VERSION "SIMULATED_UVFR_0.1"

NS_ :

BS_:

BU_: SIM_ECU SIM_GPS SIM_HARNESS TELEMETRY_NODE

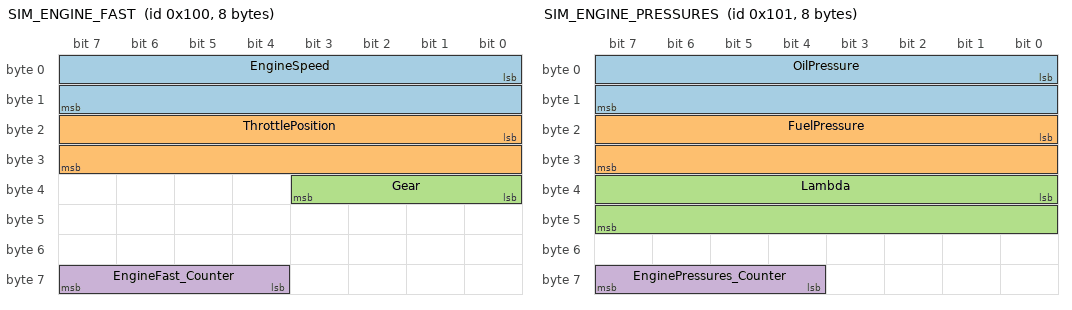
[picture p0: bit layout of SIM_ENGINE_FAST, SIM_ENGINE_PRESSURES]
BO_ 256 SIM_ENGINE_FAST: 8 SIM_ECU
 SG_ EngineSpeed : 0|16@1+ (1,0) [0|16000] "rpm" TELEMETRY_NODE
 SG_ ThrottlePosition : 16|16@1+ (0.1,0) [0|100] "%" TELEMETRY_NODE
 SG_ Gear : 32|4@1+ (1,0) [0|6] "" TELEMETRY_NODE
 SG_ EngineFast_Counter : 60|4@1+ (1,0) [0|15] "" TELEMETRY_NODE

BO_ 257 SIM_ENGINE_PRESSURES: 8 SIM_ECU
 SG_ OilPressure : 0|16@1+ (0.1,0) [0|1000] "kPa" TELEMETRY_NODE
 SG_ FuelPressure : 16|16@1+ (0.1,0) [0|1000] "kPa" TELEMETRY_NODE
 SG_ Lambda : 32|16@1+ (0.001,0) [0|5] "lambda" TELEMETRY_NODE
 SG_ EnginePressures_Counter : 60|4@1+ (1,0) [0|15] "" TELEMETRY_NODE

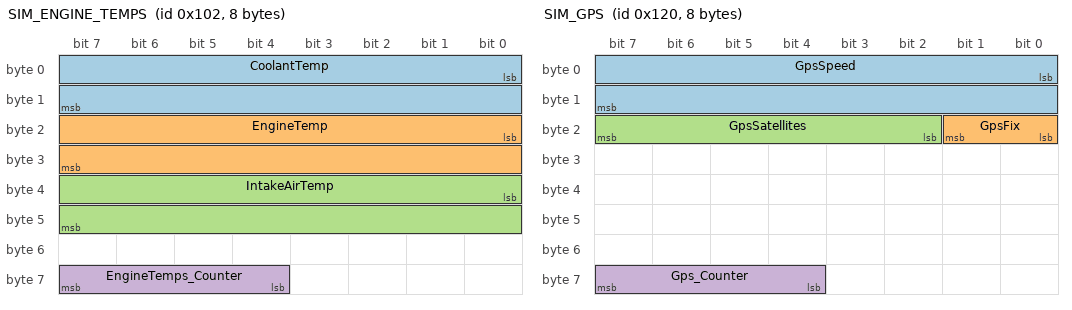
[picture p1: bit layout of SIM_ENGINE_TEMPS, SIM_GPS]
BO_ 258 SIM_ENGINE_TEMPS: 8 SIM_ECU
 SG_ CoolantTemp : 0|16@1+ (0.1,-40) [-40|150] "degC" TELEMETRY_NODE
 SG_ EngineTemp : 16|16@1+ (0.1,-40) [-40|200] "degC" TELEMETRY_NODE
 SG_ IntakeAirTemp : 32|16@1+ (0.1,-40) [-40|120] "degC" TELEMETRY_NODE
 SG_ EngineTemps_Counter : 60|4@1+ (1,0) [0|15] "" TELEMETRY_NODE

BO_ 259 SIM_ELECTRICAL: 8 SIM_ECU
 SG_ BatteryVoltage : 0|16@1+ (0.01,0) [0|20] "V" TELEMETRY_NODE
 SG_ Electrical_Counter : 60|4@1+ (1,0) [0|15] "" TELEMETRY_NODE

BO_ 272 SIM_VEHICLE: 8 SIM_ECU
 SG_ VehicleSpeed : 0|16@1+ (0.01,0) [0|200] "km/h" TELEMETRY_NODE
 SG_ Vehicle_Counter : 60|4@1+ (1,0) [0|15] "" TELEMETRY_NODE

BO_ 288 SIM_GPS: 8 SIM_GPS
 SG_ GpsSpeed : 0|16@1+ (0.01,0) [0|200] "km/h" TELEMETRY_NODE
 SG_ GpsFix : 16|2@1+ (1,0) [0|3] "" TELEMETRY_NODE
 SG_ GpsSatellites : 18|6@1+ (1,0) [0|63] "" TELEMETRY_NODE
 SG_ Gps_Counter : 60|4@1+ (1,0) [0|15] "" TELEMETRY_NODE

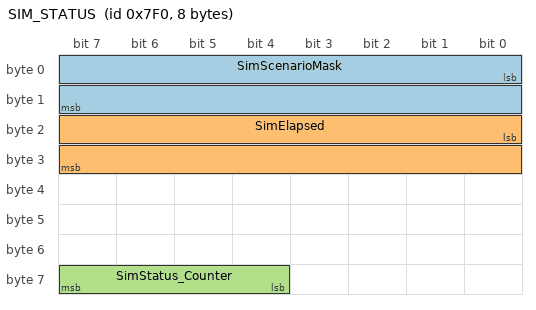
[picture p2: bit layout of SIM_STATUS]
BO_ 2032 SIM_STATUS: 8 SIM_HARNESS
 SG_ SimScenarioMask : 0|16@1+ (1,0) [0|65535] "" TELEMETRY_NODE
 SG_ SimElapsed : 16|16@1+ (1,0) [0|65535] "s" TELEMETRY_NODE
 SG_ SimStatus_Counter : 60|4@1+ (1,0) [0|15] "" TELEMETRY_NODE

CM_ "SIMULATED CAN DATABASE for the UVFR telemetry Phase 0 lab. Every message ID, signal, scaling and range in this file is SIMULATED and invented for testing. None of it is the real UVFR vehicle CAN database. Replace this file with the real DBC before using real vehicle data. Convention: a raw value with all bits set (0xFFFF for 16-bit signals) means sensor fault / not available and decodes outside the signal range.";
CM_ BU_ SIM_ECU "SIMULATED engine ECU (fake_ecu.py). Not a real UVFR node.";
CM_ BU_ SIM_GPS "SIMULATED GPS receiver (fake_ecu.py). Not a real UVFR node.";
CM_ BU_ SIM_HARNESS "Simulation harness metadata. Exists only in the Phase 0 lab, never on the car.";
CM_ BU_ TELEMETRY_NODE "Passive telemetry listener (car node). Receives only, never transmits on the vehicle bus.";
CM_ BO_ 256 "SIMULATED ID 0x100. Fast engine data at 100 Hz.";
CM_ SG_ 256 EngineSpeed "SIMULATED. Crankshaft speed.";
CM_ SG_ 256 ThrottlePosition "SIMULATED. Throttle opening.";
CM_ SG_ 256 Gear "SIMULATED. Engaged gear, 0 = neutral.";
CM_ SG_ 256 EngineFast_Counter "SIMULATED. Rolling counter, increments every transmission.";
CM_ BO_ 257 "SIMULATED ID 0x101. Engine pressures and mixture at 50 Hz.";
CM_ SG_ 257 OilPressure "SIMULATED. Engine oil gallery pressure (gauge).";
CM_ SG_ 257 FuelPressure "SIMULATED. Fuel rail pressure (gauge).";
CM_ SG_ 257 Lambda "SIMULATED. Wideband lambda, 1.0 = stoichiometric.";
CM_ SG_ 257 EnginePressures_Counter "SIMULATED. Rolling counter, increments every transmission.";
CM_ BO_ 258 "SIMULATED ID 0x102. Engine temperatures at 10 Hz.";
CM_ SG_ 258 CoolantTemp "SIMULATED. Coolant temperature at engine outlet.";
CM_ SG_ 258 EngineTemp "SIMULATED. Cylinder head temperature.";
CM_ SG_ 258 IntakeAirTemp "SIMULATED. Intake air temperature after the restrictor.";
CM_ SG_ 258 EngineTemps_Counter "SIMULATED. Rolling counter, increments every transmission.";
CM_ BO_ 259 "SIMULATED ID 0x103. Electrical system at 10 Hz.";
CM_ SG_ 259 BatteryVoltage "SIMULATED. Low-voltage system voltage at the ECU.";
CM_ SG_ 259 Electrical_Counter "SIMULATED. Rolling counter, increments every transmission.";
CM_ BO_ 272 "SIMULATED ID 0x110. Vehicle speed at 50 Hz.";
CM_ SG_ 272 VehicleSpeed "SIMULATED. Vehicle speed from front (undriven) wheel speed sensors.";
CM_ SG_ 272 Vehicle_Counter "SIMULATED. Rolling counter, increments every transmission.";
CM_ BO_ 288 "SIMULATED ID 0x120. GPS at 10 Hz.";
CM_ SG_ 288 GpsSpeed "SIMULATED. Ground speed from GPS.";
CM_ SG_ 288 GpsFix "SIMULATED. GPS fix type.";
CM_ SG_ 288 GpsSatellites "SIMULATED. Satellites used in the fix.";
CM_ SG_ 288 Gps_Counter "SIMULATED. Rolling counter, increments every transmission.";
CM_ BO_ 2032 "SIMULATION HARNESS ID 0x7F0 at 1 Hz. Reports which fault scenarios the fake ECU is running. Lab only; does not exist on any car.";
CM_ SG_ 2032 SimScenarioMask "Bitmask of active simulated fault scenarios, 0 = normal. Bit meanings are defined in simulator/scenarios.";
CM_ SG_ 2032 SimElapsed "Seconds since the fake ECU started (wraps at 65535).";
CM_ SG_ 2032 SimStatus_Counter "Rolling counter, increments every transmission.";
BA_DEF_ BO_ "GenMsgCycleTime" INT 0 65535;
BA_DEF_ "BusType" STRING ;
BA_DEF_DEF_ "GenMsgCycleTime" 0;
BA_DEF_DEF_ "BusType" "CAN";
BA_ "GenMsgCycleTime" BO_ 256 10;
BA_ "GenMsgCycleTime" BO_ 257 20;
BA_ "GenMsgCycleTime" BO_ 258 100;
BA_ "GenMsgCycleTime" BO_ 259 100;
BA_ "GenMsgCycleTime" BO_ 272 20;
BA_ "GenMsgCycleTime" BO_ 288 100;
BA_ "GenMsgCycleTime" BO_ 2032 1000;
VAL_ 256 Gear 6 "Sixth" 5 "Fifth" 4 "Fourth" 3 "Third" 2 "Second" 1 "First" 0 "Neutral" ;
VAL_ 288 GpsFix 3 "Reserved" 2 "Fix3D" 1 "Fix2D" 0 "NoFix" ;
